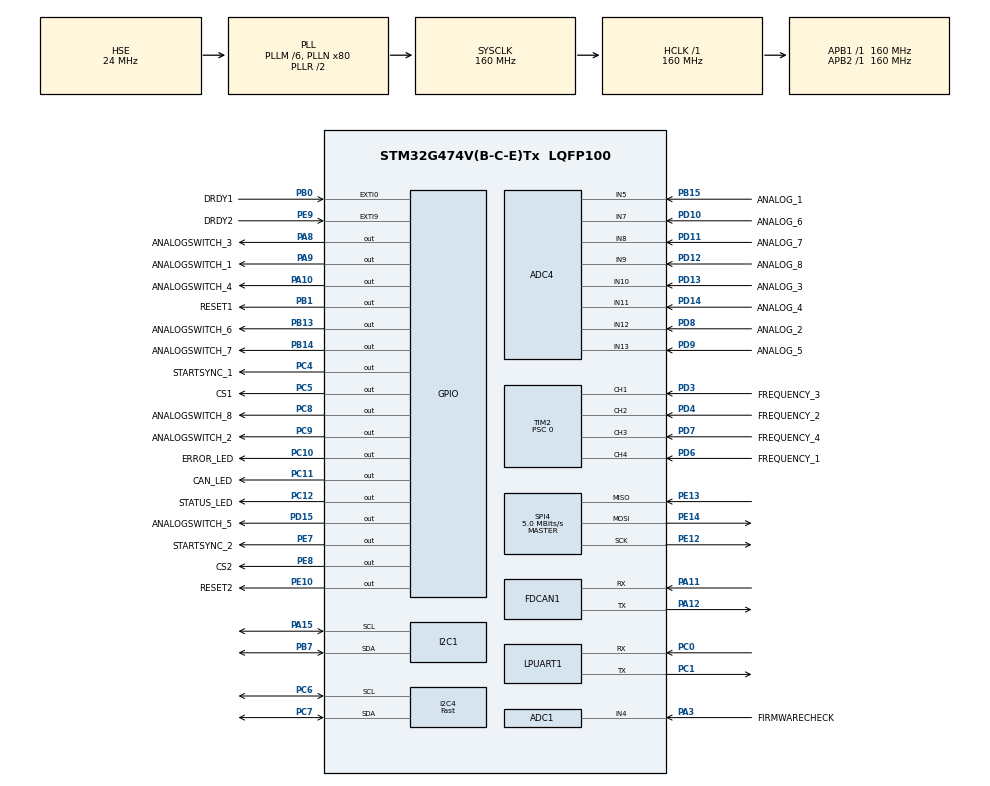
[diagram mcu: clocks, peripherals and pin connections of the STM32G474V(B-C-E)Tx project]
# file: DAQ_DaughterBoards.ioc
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ADC1.Channel-0\#ChannelRegularConversion=ADC_CHANNEL_4
ADC1.ClockPrescaler=ADC_CLOCK_SYNC_PCLK_DIV4
ADC1.NbrOfConversionFlag=1
ADC1.OffsetNumber-0\#ChannelRegularConversion=ADC_OFFSET_NONE
ADC1.Rank-0\#ChannelRegularConversion=1
ADC1.SamplingTime-0\#ChannelRegularConversion=ADC_SAMPLETIME_2CYCLES_5
ADC1.master=1
ADC4.Channel-0\#ChannelRegularConversion=ADC_CHANNEL_5
ADC4.Channel-1\#ChannelRegularConversion=ADC_CHANNEL_12
ADC4.Channel-2\#ChannelRegularConversion=ADC_CHANNEL_10
ADC4.Channel-3\#ChannelRegularConversion=ADC_CHANNEL_11
ADC4.Channel-4\#ChannelRegularConversion=ADC_CHANNEL_13
ADC4.Channel-5\#ChannelRegularConversion=ADC_CHANNEL_7
ADC4.Channel-6\#ChannelRegularConversion=ADC_CHANNEL_8
ADC4.Channel-7\#ChannelRegularConversion=ADC_CHANNEL_9
ADC4.ContinuousConvMode=ENABLE
ADC4.EOCSelection=ADC_EOC_SEQ_CONV
ADC4.EnableInjectedConversion=ENABLE
ADC4.NbrOfConversion=8
ADC4.NbrOfConversionFlag=1
ADC4.OffsetNumber-0\#ChannelRegularConversion=ADC_OFFSET_NONE
ADC4.OffsetNumber-1\#ChannelRegularConversion=ADC_OFFSET_NONE
ADC4.OffsetNumber-2\#ChannelRegularConversion=ADC_OFFSET_NONE
ADC4.OffsetNumber-3\#ChannelRegularConversion=ADC_OFFSET_NONE
ADC4.OffsetNumber-4\#ChannelRegularConversion=ADC_OFFSET_NONE
ADC4.OffsetNumber-5\#ChannelRegularConversion=ADC_OFFSET_NONE
ADC4.OffsetNumber-6\#ChannelRegularConversion=ADC_OFFSET_NONE
ADC4.OffsetNumber-7\#ChannelRegularConversion=ADC_OFFSET_NONE
ADC4.Overrun=ADC_OVR_DATA_OVERWRITTEN
ADC4.Rank-0\#ChannelRegularConversion=1
ADC4.Rank-1\#ChannelRegularConversion=2
ADC4.Rank-2\#ChannelRegularConversion=3
ADC4.Rank-3\#ChannelRegularConversion=4
ADC4.Rank-4\#ChannelRegularConversion=5
ADC4.Rank-5\#ChannelRegularConversion=6
ADC4.Rank-6\#ChannelRegularConversion=7
ADC4.Rank-7\#ChannelRegularConversion=8
ADC4.SamplingTime-0\#ChannelRegularConversion=ADC_SAMPLETIME_2CYCLES_5
ADC4.SamplingTime-1\#ChannelRegularConversion=ADC_SAMPLETIME_2CYCLES_5
ADC4.SamplingTime-2\#ChannelRegularConversion=ADC_SAMPLETIME_2CYCLES_5
ADC4.SamplingTime-3\#ChannelRegularConversion=ADC_SAMPLETIME_2CYCLES_5
ADC4.SamplingTime-4\#ChannelRegularConversion=ADC_SAMPLETIME_2CYCLES_5
ADC4.SamplingTime-5\#ChannelRegularConversion=ADC_SAMPLETIME_2CYCLES_5
ADC4.SamplingTime-6\#ChannelRegularConversion=ADC_SAMPLETIME_2CYCLES_5
ADC4.SamplingTime-7\#ChannelRegularConversion=ADC_SAMPLETIME_2CYCLES_5
Dma.ADC4.0.Direction=DMA_PERIPH_TO_MEMORY
Dma.ADC4.0.EventEnable=DISABLE
Dma.ADC4.0.Instance=DMA1_Channel3
Dma.ADC4.0.MemDataAlignment=DMA_MDATAALIGN_WORD
Dma.ADC4.0.MemInc=DMA_MINC_ENABLE
Dma.ADC4.0.Mode=DMA_CIRCULAR
Dma.ADC4.0.PeriphDataAlignment=DMA_PDATAALIGN_WORD
Dma.ADC4.0.PeriphInc=DMA_PINC_DISABLE
Dma.ADC4.0.Polarity=HAL_DMAMUX_REQ_GEN_RISING
Dma.ADC4.0.Priority=DMA_PRIORITY_LOW
Dma.ADC4.0.RequestNumber=1
Dma.ADC4.0.SignalID=NONE
Dma.ADC4.0.SyncEnable=DISABLE
Dma.ADC4.0.SyncPolarity=HAL_DMAMUX_SYNC_NO_EVENT
Dma.ADC4.0.SyncRequestNumber=1
Dma.ADC4.0.SyncSignalID=NONE
Dma.Request0=ADC4
FDCAN1.CalculateBaudRateNominal=1000000
FDCAN1.CalculateTimeBitNominal=1000
FDCAN1.CalculateTimeQuantumNominal=25.0
FDCAN1.DataPrescaler=2
FDCAN1.DataSyncJumpWidth=4
FDCAN1.DataTimeSeg1=15
FDCAN1.DataTimeSeg2=4
FDCAN1.FrameFormat=FDCAN_FRAME_FD_BRS
FDCAN1.Mode=FDCAN_MODE_NORMAL
FDCAN1.NominalPrescaler=2
FDCAN1.NominalSyncJumpWidth=2
FDCAN1.NominalTimeSeg1=31
FDCAN1.NominalTimeSeg2=8
I2C1.Timing=0x30909DEC
I2C4.Analog_Filter=I2C_ANALOGFILTER_ENABLE
I2C4.CustomTiming=Disabled
I2C4.I2C_Speed_Mode=I2C_Fast
I2C4.Timing=0x00F07BFF
Mcu.Family=STM32G4
Mcu.Name=STM32G474V(B-C-E)Tx
Mcu.Package=LQFP100
NVIC.ADC4_IRQn=true\:0\:0\:false\:false\:true\:false\:true\:true\:true
NVIC.DMA1_Channel3_IRQn=true\:0\:0\:false\:false\:true\:true\:false\:true\:true
NVIC.EXTI0_IRQn=true\:1\:0\:true\:false\:true\:false\:true\:true\:true
NVIC.EXTI9_5_IRQn=true\:1\:0\:true\:false\:true\:false\:true\:true\:true
NVIC.FDCAN1_IT0_IRQn=true\:0\:0\:false\:false\:true\:false\:true\:true\:true
NVIC.FDCAN1_IT1_IRQn=true\:0\:0\:false\:false\:true\:false\:true\:true\:true
NVIC.I2C4_ER_IRQn=true\:0\:0\:false\:false\:true\:false\:true\:true\:true
NVIC.I2C4_EV_IRQn=true\:0\:0\:false\:false\:true\:false\:true\:true\:true
NVIC.PriorityGroup=NVIC_PRIORITYGROUP_4
NVIC.SPI4_IRQn=true\:0\:0\:false\:false\:true\:false\:true\:true\:true
NVIC.TIM2_IRQn=true\:0\:0\:false\:false\:true\:false\:true\:true\:true
NVIC.TIM6_DAC_IRQn=true\:15\:0\:false\:false\:true\:false\:false\:true\:true
NVIC.TimeBase=TIM6_DAC_IRQn
NVIC.TimeBaseIP=TIM6
PA10.GPIO_Label=ANALOGSWITCH_4
PA10.Signal=GPIO_Output
PA11.Mode=FDCAN_Activate
PA11.Signal=FDCAN1_RX
PA12.Mode=FDCAN_Activate
PA12.Signal=FDCAN1_TX
PA13.Mode=Trace_Asynchronous_SW
PA13.Signal=SYS_JTMS-SWDIO
PA14.Mode=Trace_Asynchronous_SW
PA14.Signal=SYS_JTCK-SWCLK
PA15.Mode=I2C
PA15.Signal=I2C1_SCL
PA3.GPIO_Label=FIRMWARECHECK
PA3.Mode=IN4-Single-Ended
PA3.Signal=ADC1_IN4
PA8.GPIO_Label=ANALOGSWITCH_3
PA8.Signal=GPIO_Output
PA9.GPIO_Label=ANALOGSWITCH_1
PA9.Signal=GPIO_Output
PB0.GPIO_Label=DRDY1
PB0.GPIO_ModeDefaultEXTI=GPIO_MODE_IT_FALLING
PB0.GPIO_PuPd=GPIO_PULLUP
PB0.Signal=GPXTI0
PB1.GPIO_Label=RESET1
PB1.Signal=GPIO_Output
PB13.GPIO_Label=ANALOGSWITCH_6
PB13.Signal=GPIO_Output
PB14.GPIO_Label=ANALOGSWITCH_7
PB14.Signal=GPIO_Output
PB15.GPIO_Label=ANALOG_1
PB15.Mode=IN5-Single-Ended
PB15.Signal=ADC4_IN5
PB3.Mode=Trace_Asynchronous_SW
PB3.Signal=SYS_JTDO-SWO
PB7.Mode=I2C
PB7.Signal=I2C1_SDA
PC0.Mode=Asynchronous
PC0.Signal=LPUART1_RX
PC1.Mode=Asynchronous
PC1.Signal=LPUART1_TX
PC10.GPIO_Label=ERROR_LED
PC10.Signal=GPIO_Output
PC11.GPIO_Label=CAN_LED
PC11.Signal=GPIO_Output
PC12.GPIO_Label=STATUS_LED
PC12.Signal=GPIO_Output
PC4.GPIO_Label=STARTSYNC_1
PC4.Signal=GPIO_Output
PC5.GPIO_Label=CS1
PC5.Signal=GPIO_Output
PC6.GPIO_Speed=GPIO_SPEED_FREQ_VERY_HIGH
PC6.Mode=I2C
PC6.Signal=I2C4_SCL
PC7.GPIO_Speed=GPIO_SPEED_FREQ_VERY_HIGH
PC7.Mode=I2C
PC7.Signal=I2C4_SDA
PC8.GPIO_Label=ANALOGSWITCH_8
PC8.Signal=GPIO_Output
PC9.GPIO_Label=ANALOGSWITCH_2
PC9.Signal=GPIO_Output
PD10.GPIO_Label=ANALOG_6
PD10.Mode=IN7-Single-Ended
PD10.Signal=ADC4_IN7
PD11.GPIO_Label=ANALOG_7
PD11.Mode=IN8-Single-Ended
PD11.Signal=ADC4_IN8
PD12.GPIO_Label=ANALOG_8
PD12.Mode=IN9-Single-Ended
PD12.Signal=ADC4_IN9
PD13.GPIO_Label=ANALOG_3
PD13.Mode=IN10-Single-Ended
PD13.Signal=ADC4_IN10
PD14.GPIO_Label=ANALOG_4
PD14.Mode=IN11-Single-Ended
PD14.Signal=ADC4_IN11
PD15.GPIO_Label=ANALOGSWITCH_5
PD15.Signal=GPIO_Output
PD3.GPIO_Label=FREQUENCY_3
PD3.GPIO_PuPd=GPIO_PULLDOWN
PD3.Signal=S_TIM2_CH1
PD4.GPIO_Label=FREQUENCY_2
PD4.GPIO_PuPd=GPIO_PULLDOWN
PD4.Signal=S_TIM2_CH2
PD6.GPIO_Label=FREQUENCY_1
PD6.GPIO_PuPd=GPIO_PULLDOWN
PD6.Signal=S_TIM2_CH4
PD7.GPIO_Label=FREQUENCY_4
PD7.GPIO_PuPd=GPIO_PULLDOWN
PD7.Signal=S_TIM2_CH3
PD8.GPIO_Label=ANALOG_2
PD8.Mode=IN12-Single-Ended
PD8.Signal=ADC4_IN12
PD9.GPIO_Label=ANALOG_5
PD9.Mode=IN13-Single-Ended
PD9.Signal=ADC4_IN13
PE10.GPIO_Label=RESET2
PE10.Signal=GPIO_Output
PE12.Mode=Full_Duplex_Master
PE12.Signal=SPI4_SCK
PE13.Mode=Full_Duplex_Master
PE13.Signal=SPI4_MISO
PE14.Mode=Full_Duplex_Master
PE14.Signal=SPI4_MOSI
PE7.GPIO_Label=STARTSYNC_2
PE7.Signal=GPIO_Output
PE8.GPIO_Label=CS2
PE8.Signal=GPIO_Output
PE9.GPIO_Label=DRDY2
PE9.GPIO_ModeDefaultEXTI=GPIO_MODE_IT_FALLING
PE9.GPIO_PuPd=GPIO_PULLUP
PE9.Signal=GPXTI9
PF0-OSC_IN.Mode=HSE-External-Oscillator
PF0-OSC_IN.Signal=RCC_OSC_IN
PF1-OSC_OUT.Mode=HSE-External-Oscillator
PF1-OSC_OUT.Signal=RCC_OSC_OUT
ProjectManager.HeapSize=0x200
ProjectManager.StackSize=0x400
ProjectManager.TargetToolchain=STM32CubeIDE
RCC.ADC12Freq_Value=160000000
RCC.ADC345Freq_Value=160000000
RCC.AHBFreq_Value=160000000
RCC.APB1Freq_Value=160000000
RCC.APB1TimFreq_Value=160000000
RCC.APB2Freq_Value=160000000
RCC.APB2TimFreq_Value=160000000
RCC.CortexFreq_Value=160000000
RCC.EXTERNAL_CLOCK_VALUE=12288000
RCC.FDCANCLockSelection=RCC_FDCANCLKSOURCE_PLL
RCC.HCLKFreq_Value=160000000
RCC.HSE_VALUE=24000000
RCC.HSI48_VALUE=48000000
RCC.HSI_VALUE=16000000
RCC.LSE_VALUE=32768
RCC.PLLM=RCC_PLLM_DIV6
RCC.PLLN=80
RCC.PLLQ=RCC_PLLQ_DIV4
RCC.PLLSourceVirtual=RCC_PLLSOURCE_HSE
RCC.SYSCLKFreq_VALUE=160000000
RCC.SYSCLKSource=RCC_SYSCLKSOURCE_PLLCLK
RCC.USBFreq_Value=80000000
RCC.VCOOutputFreq_Value=320000000
SH.S_TIM2_CH1.0=TIM2_CH1,Input_Capture1_from_TI1
SH.S_TIM2_CH2.0=TIM2_CH2,Input_Capture2_from_TI2
SH.S_TIM2_CH3.0=TIM2_CH3,Input_Capture3_from_TI3
SH.S_TIM2_CH4.0=TIM2_CH4,Input_Capture4_from_TI4
SPI4.BaudRatePrescaler=SPI_BAUDRATEPRESCALER_32
SPI4.CLKPhase=SPI_PHASE_2EDGE
SPI4.CRCCalculation=SPI_CRCCALCULATION_DISABLE
SPI4.CalculateBaudRate=5.0 MBits/s
SPI4.DataSize=SPI_DATASIZE_8BIT
SPI4.Direction=SPI_DIRECTION_2LINES
SPI4.Mode=SPI_MODE_MASTER
SPI4.VirtualType=VM_MASTER
STMicroelectronics.X-CUBE-AZRTOS-G4.2.0.0.TX_APP_GENERATE_INIT_CODE=false
STMicroelectronics.X-CUBE-AZRTOS-G4.2.0.0.TX_APP_MEM_POOL_SIZE=100000
STMicroelectronics.X-CUBE-AZRTOS-G4.2.0.0.TX_MINIMUM_STACK=200
STMicroelectronics.X-CUBE-AZRTOS-G4.2.0.0.TX_TIMER_TICKS_PER_SECOND=1000
STMicroelectronics.X-CUBE-AZRTOS-G4.2.0.0.ThreadXCcRTOSJjThreadXJjCore=true
STMicroelectronics.X-CUBE-AZRTOS-G4.2.0.0_IsAnAzureRtosMw=true
TIM2.Channel-Input_Capture1_from_TI1=TIM_CHANNEL_1
TIM2.Channel-Input_Capture2_from_TI2=TIM_CHANNEL_2
TIM2.Channel-Input_Capture3_from_TI3=TIM_CHANNEL_3
TIM2.Channel-Input_Capture4_from_TI4=TIM_CHANNEL_4
TIM2.Prescaler=0
VP_CRC_VS_CRC.Mode=CRC_Activate
VP_STMicroelectronics.X-CUBE-AZRTOS-G4_VS_RTOSJjThreadX_6.2.0_2.0.0.Mode=RTOSJjThreadX
VP_SYS_VS_DBSignals.Mode=DisableDeadBatterySignals
VP_SYS_VS_tim6.Mode=TIM6
VP_SYS_V_VREFBUF.Mode=ExternalMode
board=custom

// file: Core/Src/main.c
/* USER CODE BEGIN Header */
/**
  ******************************************************************************
  * @file           : main.c
  * @brief          : Main program body
  ******************************************************************************
  * @attention
  *
  * Copyright (c) 2024 STMicroelectronics.
  * All rights reserved.
  *
  * This software is licensed under terms that can be found in the LICENSE file
  * in the root directory of this software component.
  * If no LICENSE file comes with this software, it is provided AS-IS.
  *
  ******************************************************************************
  */
/* USER CODE END Header */
#include "app_threadx.h"
#include "main.h"
#include "adc.h"
#include "crc.h"
#include "dma.h"
#include "fdcan.h"
#include "i2c.h"
#include "usart.h"
#include "spi.h"
#include "tim.h"
#include "gpio.h"

/* USER CODE BEGIN Includes */
#include "threadx.hpp"
/* USER CODE END Includes */

void SystemClock_Config(void);

int main(void)
{

  /* MCU Configuration--------------------------------------------------------*/

  /* Reset of all peripherals, Initializes the Flash interface and the Systick. */
  HAL_Init();

  /* Configure the system clock */
  SystemClock_Config();

  /* Initialize all configured peripherals */
  MX_GPIO_Init();
  MX_DMA_Init();
  MX_FDCAN1_Init();
  MX_TIM2_Init();
  MX_CRC_Init();
  MX_ADC4_Init();
  MX_SPI4_Init();
  MX_ADC1_Init();
  MX_I2C1_Init();
  MX_I2C4_Init();
  MX_LPUART1_UART_Init();

  MX_ThreadX_Init();

  /* We should never get here as control is now taken by the scheduler */

  /* Infinite loop */
  while (1)
  {

  }
}

void SystemClock_Config(void)
{
  RCC_OscInitTypeDef RCC_OscInitStruct = {0};
  RCC_ClkInitTypeDef RCC_ClkInitStruct = {0};

  /** Configure the main internal regulator output voltage
  */
  HAL_PWREx_ControlVoltageScaling(PWR_REGULATOR_VOLTAGE_SCALE1_BOOST);

  /** Initializes the RCC Oscillators according to the specified parameters
  * in the RCC_OscInitTypeDef structure.
  */
  RCC_OscInitStruct.OscillatorType = RCC_OSCILLATORTYPE_HSE;
  RCC_OscInitStruct.HSEState = RCC_HSE_ON;
  RCC_OscInitStruct.PLL.PLLState = RCC_PLL_ON;
  RCC_OscInitStruct.PLL.PLLSource = RCC_PLLSOURCE_HSE;
  RCC_OscInitStruct.PLL.PLLM = RCC_PLLM_DIV6;
  RCC_OscInitStruct.PLL.PLLN = 80;
  RCC_OscInitStruct.PLL.PLLP = RCC_PLLP_DIV2;
  RCC_OscInitStruct.PLL.PLLQ = RCC_PLLQ_DIV4;
  RCC_OscInitStruct.PLL.PLLR = RCC_PLLR_DIV2;
  if (HAL_RCC_OscConfig(&RCC_OscInitStruct) != HAL_OK)
  {
    Error_Handler();
  }

  /** Initializes the CPU, AHB and APB buses clocks
  */
  RCC_ClkInitStruct.ClockType = RCC_CLOCKTYPE_HCLK|RCC_CLOCKTYPE_SYSCLK
                              |RCC_CLOCKTYPE_PCLK1|RCC_CLOCKTYPE_PCLK2;
  RCC_ClkInitStruct.SYSCLKSource = RCC_SYSCLKSOURCE_PLLCLK;
  RCC_ClkInitStruct.AHBCLKDivider = RCC_SYSCLK_DIV1;
  RCC_ClkInitStruct.APB1CLKDivider = RCC_HCLK_DIV1;
  RCC_ClkInitStruct.APB2CLKDivider = RCC_HCLK_DIV1;

  if (HAL_RCC_ClockConfig(&RCC_ClkInitStruct, FLASH_LATENCY_4) != HAL_OK)
  {
    Error_Handler();
  }
}

void HAL_TIM_PeriodElapsedCallback(TIM_HandleTypeDef *htim)
{
  if (htim->Instance == TIM6) {
    HAL_IncTick();
  }
}

void Error_Handler(void)
{
  __disable_irq();
  while (1)
  {
  }
}
